# D2522AA register map
Vendor: Dialog; Series: D2522AA; File version: 1.2
CPU: CM0 r1p0, little endian, MPU, FPU, 3 interrupt priority bits
Registers are 32-bit, read-write, reset 0x0 unless marked. A register's access mark holds for its fields unless they carry their own. Offsets are from the block's base; [hi:lo] are bit positions; {n}, {i} and the like mark numbered series; <NAME> marks a mode.

## ADPLL — ADPLL registers
Base 0x40022000
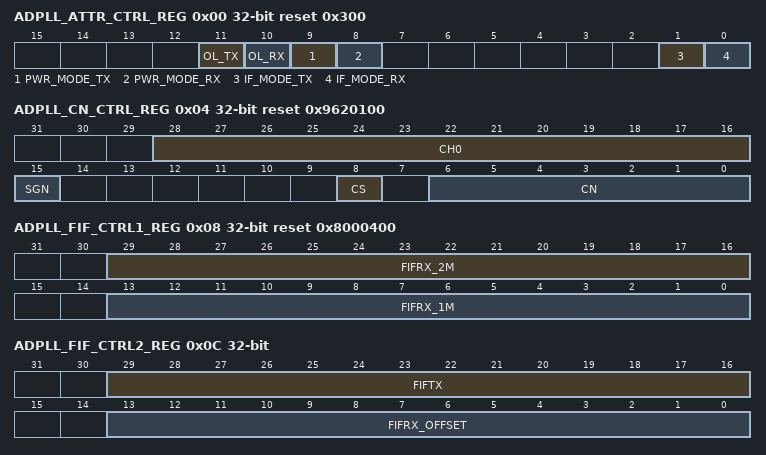
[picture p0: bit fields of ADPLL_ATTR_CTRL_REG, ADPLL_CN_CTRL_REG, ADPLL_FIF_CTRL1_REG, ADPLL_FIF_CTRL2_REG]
0x00 ADPLL_ATTR_CTRL_REG reset 0x300
  [11] OL_TX — Enable open-loop mode for TX. 0: Disabled (default) 1: Enabled
  [10] OL_RX — Enable open-loop mode for RX. 0: Disabled (default) 1: Enabled
  [9] PWR_MODE_TX — Power mode option to be used in TX. 0: Low power (default) 1: High performance
  [8] PWR_MODE_RX — Power mode option to be used in RX. 0: Low power (default) 1: High performance
  [1] IF_MODE_TX — IF mode option to be used in TX. 0: 1 Mbps (default) 1: 2 Mbps
  [0] IF_MODE_RX — IF mode option to be used in RX. 0: 1 Mbps (default) 1: 2 Mbps
0x04 ADPLL_CN_CTRL_REG reset 0x9620100
  [28:16] CH0 — Channel 0 frequency in MHz (CH0) (ufix13) default: 2402
  [15] SGN — Sign bit for the channel step 0: positive (default) 1: negative
  [8] CS — Channel spacing. 0: 1 MHz spacing 1: 2 MHz spacing (default)
  [6:0] CN — Channel number. Default: 0
0x08 ADPLL_FIF_CTRL1_REG reset 0x8000400
  [29:16] FIFRX_2M — IF frequency (in MHz) used in 2 Mbps RX mode sfix(14,10) - 1 bit sign, 3 bits integer, 10 bits fractional for MHz unit.
  [13:0] FIFRX_1M — IF frequency (in MHz) used in 1 Mbps RX mode sfix(14,10) - 1 bit sign, 3 bits integer, 10 bits fractional for MHz unit.
0x0C ADPLL_FIF_CTRL2_REG
  [29:16] FIFTX — IF frequency (in MHz) used in TX mode sfix(14,10) - 1 bit sign, 3 bits integer, 10 bits fractional for MHz unit.
  [13:0] FIFRX_OFFSET — Offset for the IF frequency (in MHz) in RX mode. sfix(14,10) - 1 bit sign, 3 bits integer, 10 bits fractional for MHz unit.
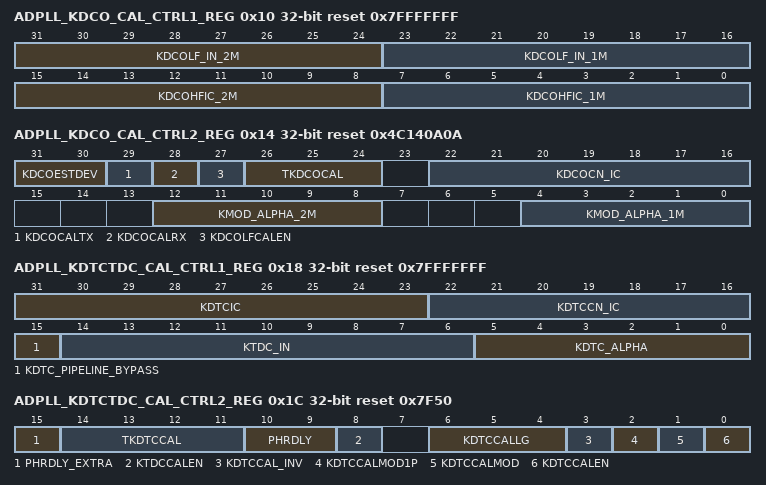
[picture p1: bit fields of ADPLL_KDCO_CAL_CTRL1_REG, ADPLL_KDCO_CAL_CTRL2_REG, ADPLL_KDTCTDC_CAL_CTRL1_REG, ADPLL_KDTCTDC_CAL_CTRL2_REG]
0x10 ADPLL_KDCO_CAL_CTRL1_REG reset 0x7FFFFFFF (reset mask 0x7FFFFFFF)
  [31:24] KDCOLF_IN_2M — Gain setting for the low frequency path in case of not using the calibrated KDCOHF for 2M mode (uint8).
  [23:16] KDCOLF_IN_1M — Gain setting for the low frequency path in case of not using the calibrated KDCOHF for 1M mode (uint8).
  [15:8] KDCOHFIC_2M — Initial gain setting for the high frequency path for 2M mode (uint8).
  [7:0] KDCOHFIC_1M — Initial gain setting for the high frequency path for 1M mode (uint8).
0x14 ADPLL_KDCO_CAL_CTRL2_REG reset 0x4C140A0A (reset mask 0x7FFFFFFF)
  [31:30] KDCOESTDEV — Frequency deviation used for KDCO estimation: 0: 500 kHz 1: 250 kHz (default) 2: 125 kHz 3: 62.5 kHz
  [29] KDCOCALTX — Enable for KDCO calibration in transmit mode.
  [28] KDCOCALRX — Enable for KDCO calibration in receive mode.
  [27] KDCOLFCALEN — Enable the use of the (calibrated) value for KDCOHF for the low frequency path.
  [26:24] TKDCOCAL — Time spend for KDCO calibration settling: 0: 0.5 us 16 1: 1 us 32 2: 2 us 64 3: 4 us 128 4: 8 us
  [22:16] KDCOCN_IC — Initial condition for channel number related to calibration result.
  [12:8] KMOD_ALPHA_2M — KDCOHF channel dependent trimming constant for 2M mode. 0: No trimming. >0: KDCOHF is modified with a factor: 1-SGNx(KMOD_ALPHA_2M)x(CN-CN_CAL_RD)/4096
  [4:0] KMOD_ALPHA_1M — KDCOHF channel dependent trimming constant for 1M mode. 0: No trimming. >0: KDCOHF is modified with a factor: 1-SGNx(KMOD_ALPHA_1M)x(CN-CN_CAL_RD)/4096
0x18 ADPLL_KDTCTDC_CAL_CTRL1_REG reset 0x7FFFFFFF (reset mask 0x7FFFFFFF)
  [31:23] KDTCIC — Initial condition for the DTC gain correction.
  [22:16] KDTCCN_IC — Initial condition for channel number related to calibration result.
  [15] KDTC_PIPELINE_BYPASS — Bypass the extra register on prv_phr.
  [14:6] KTDC_IN — TDC gain setting in case of not using the calibrated gain setting.
  [5:0] KDTC_ALPHA — KDTC channel dependent trimming constant. 0: No trimming. >0: KDTC is modified with a factor: 1-SGNx(KDTC_ALPHA)x(CN-CN_CAL_RD)/16384
0x1C ADPLL_KDTCTDC_CAL_CTRL2_REG reset 0x7F50
  [15] PHRDLY_EXTRA
  [14:11] TKDTCCAL — Time spend waiting for DTC calibration (0-15) 0 - 15 us t = tkdtccal/2.
  [10:9] PHRDLY — Delay phr used for kdtc calibration by 1-4 samples, default: 3 samples (2).
  [8] KTDCCALEN — Enable calibration of TDC via DTC calibration.
  [6:4] KDTCCALLG — Loopgain setting used for DTC calibration.
  [3] KDTCCAL_INV — Invert sign of kdtc calibration loop (default: 0).
  [2] KDTCCALMOD1P — Chicken bit to change phase of KDTC cal mode 1 phase.
  [1] KDTCCALMOD — Mode select for KDTC alogrithm: 0: Just-in-time algorithm (least intrusive) 1: Interger lock to Fref/2 and use second clock phase for calibration (no issue with local optimum)
  [0] KDTCCALEN — Enable DTC calibration.
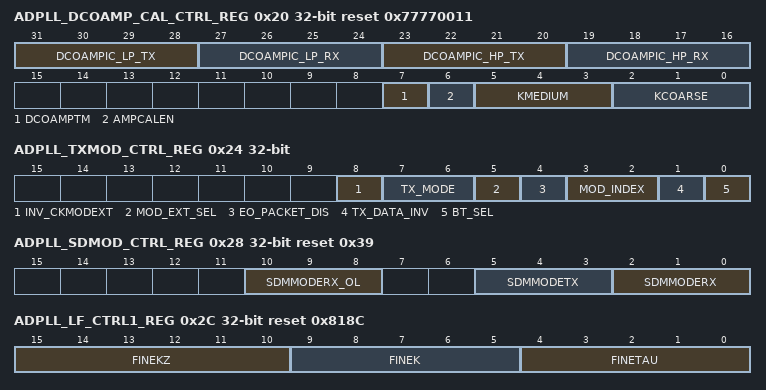
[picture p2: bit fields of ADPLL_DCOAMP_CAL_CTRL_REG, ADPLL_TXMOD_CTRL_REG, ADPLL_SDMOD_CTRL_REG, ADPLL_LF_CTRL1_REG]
0x20 ADPLL_DCOAMP_CAL_CTRL_REG reset 0x77770011 (reset mask 0x7FFFFFFF)
  [31:28] DCOAMPIC_LP_TX — Initial condition for the DCO amplitude setting, for Low Power TX mode..
  [27:24] DCOAMPIC_LP_RX — Initial condition for the DCO amplitude setting, for Low Power RX mode..
  [23:20] DCOAMPIC_HP_TX — Initial condition for the DCO amplitude setting, for High Performance TX mode..
  [19:16] DCOAMPIC_HP_RX — Initial condition for the DCO amplitude setting, for High Performance RX mode..
  [7] DCOAMPTM — Time spend to perform DCO amplitude calibration 0: 1 us 1: 2 us
  [6] AMPCALEN — Enable DCO amplitude calibration.
  [5:3] KMEDIUM — Proportional gain setting for medium tuning.
  [2:0] KCOARSE — Proportional gain setting for coarse tuning.
0x24 ADPLL_TXMOD_CTRL_REG
  [8] INV_CKMODEXT — Invert the clock, which captures the external modulated data.
  [7:6] TX_MODE — Two-point modulation MUX: 0,3: mod_hf = mod_in mod_lf = mod_in 1: mod_hf = 0 mod_lf = mod_in 2: mod_hf = mod_in mod_lf = 0
  [5] MOD_EXT_SEL — 0: Normal operation 1: User externally provided value for the modulation
  [4] EO_PACKET_DIS — The block will normally detect the end of a data packet by the missing tx_data_en pulses. The outputs will be smoothly return to zero when an end of a data packet has been deteted. The end of a data packet detected can be disabled by setting eo_packet_dis = 1. This is normally/never used and eo_packet_dis should always be set to zero.
  [3:2] MOD_INDEX — Modulation index selection: 0: h = 1/2 (dF = 250 kHz) 1 h = 1/4 (dF = 125 kHz): 2: h = 17/32 (dF = 266 kHz) 3: h = 35/64 (dF = 273 kHz)
  [1] TX_DATA_INV — Select polarity of the modulation prior to pulse shaping 0: Normal operation 1: Invert modulation signal
  [0] BT_SEL — The BT product for the Gaussian pulse can take the values 0.5 or 0.6. 0: BT = 0.5 1: BT = 0.6
0x28 ADPLL_SDMOD_CTRL_REG reset 0x39
  [10:8] SDMMODERX_OL — Open Loop Sigma delta modulator mode : 0: Disabled 1: MASH I 3: MASH II 5: MASH I + with dithering 7: MASH II + with dithering
  [5:3] SDMMODETX — Sigma delta modulator mode : 0: Disabled 1: MASH I 3: MASH II 5: MASH I + with dithering 7: MASH II + with dithering
  [2:0] SDMMODERX — Sigma delta modulator mode : 0: Disabled 1: MASH I 3: MASH II 5: MASH I + with dithering 7: MASH II + with dithering
0x2C ADPLL_LF_CTRL1_REG reset 0x818C
  [15:10] FINEKZ — Corner frequency setting of the first order low-pass filter that is used for tuning the fine bank.
  [9:5] FINEK — Loopfilter loopgain frequency during fine tuning.
  [4:0] FINETAU — First order low-pass filter c.rst_ner frequency during fine tuning.
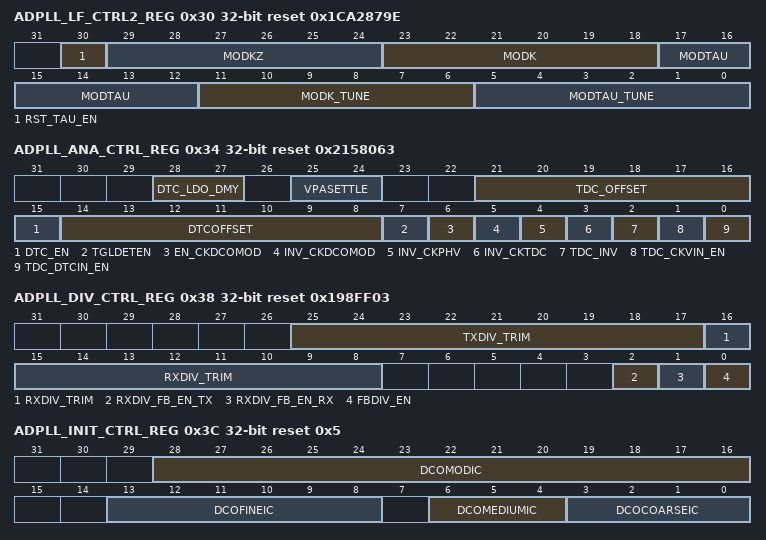
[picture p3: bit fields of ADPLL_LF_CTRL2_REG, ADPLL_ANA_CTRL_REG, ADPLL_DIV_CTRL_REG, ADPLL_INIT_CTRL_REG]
0x30 ADPLL_LF_CTRL2_REG reset 0x1CA2879E
  [30] RST_TAU_EN — Enable state machine to control reset of tau filter.
  [29:24] MODKZ — Loopgain setting of the loop-filter that is used for tuning the MOD bank.
  [23:18] MODK — Corner frequency setting of the zero filter that is used for tuning the MOD bank.
  [17:12] MODTAU — Corner frequency setting of the first order low-pass filter that is used for tuning the MOD bank.
  [11:6] MODK_TUNE — Loopfilter loopgain frequency during mod tuning.
  [5:0] MODTAU_TUNE — First order low-pass filter c.rst_ner frequency during mod tuning.
0x34 ADPLL_ANA_CTRL_REG reset 0x2158063
  [28:27] DTC_LDO_DMY — Control signal for TDC/DTC/VPA LDO dummy loads.
  [25:24] VPASETTLE — Allow TDC after an edge on VPA en 00: No 01: Rising 10: Falling 11: Both edges
  [21:16] TDC_OFFSET — TDC offset that is to be subtracted from the binary input to obtain the signed value (default 10.5).
  [15] DTC_EN — Enable DTC
  [14:8] DTCOFFSET — Offset Added to DTC output Only used for test purpose default = 0
  [7] TGLDETEN — Enable PHV toggle and TDC Bubble detection.
  [6] EN_CKDCOMOD — Enable clock registering the dcomod (default = 1).
  [5] INV_CKDCOMOD — Invert clock polarity of the clock registering the dcomod.
  [4] INV_CKPHV — Invert clock polarity of the clock registering the variable phase accumulator.
  [3] INV_CKTDC — Invert clock polarity of the clock registering the time to digital converter.
  [2] TDC_INV — Invert sign of the time to digital converter output.
  [1] TDC_CKVIN_EN — Enable ckv input of the TDC.
  [0] TDC_DTCIN_EN
0x38 ADPLL_DIV_CTRL_REG reset 0x198FF03
  [25:17] TXDIV_TRIM — Tx divider trim value.
  [16:8] RXDIV_TRIM — Rx divider trim value.
  [2] RXDIV_FB_EN_TX — Enable rxdiv for FB in TX mode. 0: Disable (default) 1: Enable
  [1] RXDIV_FB_EN_RX — Enable rxdiv for FB in RX mode. 0: Disable (default) 1: Enable
  [0] FBDIV_EN — Feedback divider enable 1: Enabled 0: Disabled. If diabled both feedback and RF output clock will be disabled. This bit is intended for test purposes (not for normal usage).
0x3C ADPLL_INIT_CTRL_REG reset 0x5
  [28:16] DCOMODIC — Initial condition for fine cap bank. (signed)
  [13:8] DCOFINEIC — Initial condition for fine cap bank. (signed)
  [6:4] DCOMEDIUMIC — Initial condition for medium cap bank. (signed)
  [3:0] DCOCOARSEIC — Initial condition for coarse cap bank. (signed)
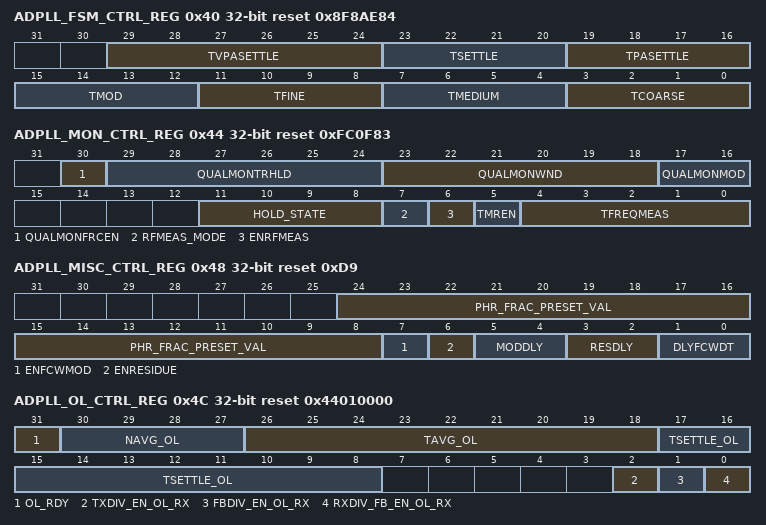
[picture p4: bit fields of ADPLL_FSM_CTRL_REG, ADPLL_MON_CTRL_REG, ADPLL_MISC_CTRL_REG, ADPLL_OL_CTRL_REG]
0x40 ADPLL_FSM_CTRL_REG reset 0x8F8AE84
  [29:24] TVPASETTLE — Settling time required after vpa disable.
  [23:20] TSETTLE — Time spend waiting for settling 0 - 15: 0 - 7.5 us (t = TSETTLE/2)
  [19:16] TPASETTLE — Time spend waiting for PA to settle 0 - 15: 0 - 7.5 us (t = TPASETTLE/2)
  [15:12] TMOD — Time spend for fine tuning 0 - 15: 0 - 15 us (t = TMOD)
  [11:8] TFINE — Time spend for fine tuning 0 - 15: 0 - 15 us (t = TFINE)
  [7:4] TMEDIUM — Time spend for medium tuning 0 - 15: 0 - 7.5 us (t = TMEDIUM/2) If < 1 us and amplitude calibration is enabled TMEDIUM = 1 us.
  [3:0] TCOARSE — Time spend for coarse tuning 0 - 15: 0 - 7.5 us (t = TCOARSE/2)
0x44 ADPLL_MON_CTRL_REG reset 0xFC0F83
  [30] QUALMONFRCEN — Force enable of the clock quality monitor.
  [29:24] QUALMONTRHLD — Clock quality monitoring threshold.
  [23:18] QUALMONWND — Clock quality monitoring window length.
  [17:16] QUALMONMOD — Clock quality monitoring mode: 0: Highpass output 1: TDC 2: Lowpass output 3: Loop filter output
  [11:8] HOLD_STATE — Set a break point at which the tuning state machine will hold it's state.
  [7] RFMEAS_MODE — RF measurement mode for the Divider calibrations. 0 : Jerzy RF measurement. 1 (default): RF measurement for divider calibration.
  [6] ENRFMEAS — Enable open loop frequency measurement.
  [5] TMREN — Enable timer for measuring PLL settling time.
  [4:0] TFREQMEAS — Frequency measurement time Two lsb's form the linear part, the three MSB's are the exponent Time [us] = 0.5+((4+lin)*(2^(exp-1))) tfreqmeas Time [us] 0: 2.5 1: 3 2: 3.5 3: 4 4: 4.5 5: 5.5 6: 6.5 7: 7.5 8: 8.5 9: 10.5 10: 12.5 11: 14.5 12: 16.5 13: 20.5 14: 24.5 15: 28.5 16: 32.5 17: 40.5 18: 48.5 19: 56.5 20: 64.5 21: 80.5 22: 96.5 23: 112.5 24: 128.5 25: 160.5 26: 192.5 27: 224.5 28: 256.5 29: 320.5 30: 384.5 31: 448.5
0x48 ADPLL_MISC_CTRL_REG reset 0xD9
  [24:8] PHR_FRAC_PRESET_VAL — Controls the set level of the DCO amplitude detector.
  [7] ENFCWMOD — Enable two point modulation.
  [6] ENRESIDUE — Enable residue correction .
  [5:4] MODDLY — Delay modulation (injected at the capcitor bank) by 0-3 samples.
  [3:2] RESDLY — Delay residue by 0-3 samples.
  [1:0] DLYFCWDT — Delay reference path of the two point modulation.
0x4C ADPLL_OL_CTRL_REG reset 0x44010000 (reset mask 0x7FFFFFFF)
  [31] OL_RDY ro — Read out openloop_rdy output before gating with rxbit status.
  [30:27] NAVG_OL — Averaging ratio. Division for averaging: 2NAVG_OL.
  [26:18] TAVG_OL — Number of dcomod samples to be averaged. TAVG_OL = 2NAVG_OL)
  [17:8] TSETTLE_OL — Number of clocks cycles to wait for dcomod to settle, before starting averaging for open loop mode.
  [2] TXDIV_EN_OL_RX — txdiv_en value to be used in open loop mode when in RX.
  [1] FBDIV_EN_OL_RX — fbdiv_en value to be used in open loop mode when in RX.
  [0] RXDIV_FB_EN_OL_RX — rxdiv_fb_en value to be used in open loop mode when in RX.
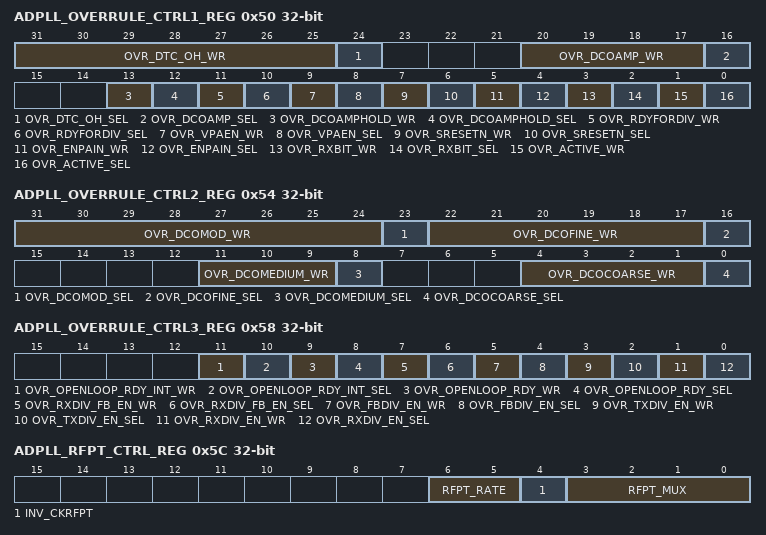
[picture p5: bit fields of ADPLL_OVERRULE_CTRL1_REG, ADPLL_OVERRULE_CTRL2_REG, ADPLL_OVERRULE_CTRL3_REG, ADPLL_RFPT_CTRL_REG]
0x50 ADPLL_OVERRULE_CTRL1_REG (reset mask 0x7FFFFFFF)
  [31:25] OVR_DTC_OH_WR — Overrule value (binary) for the dtc_oh.
  [24] OVR_DTC_OH_SEL — Overrule dtc_oh output. 0: Normal function (default) 1: Overrule dtc_oh output by OVR_DTC_OH_WR
  [20:17] OVR_DCOAMP_WR — Overrule value for the dcoamp.
  [16] OVR_DCOAMP_SEL — Overrule dcoamp output. 0: Normal function (default) 1: Overrule dcoamp output by OVR_DCOAMP_WR
  [13] OVR_DCOAMPHOLD_WR — Overrule value for the dcoamp_hold..
  [12] OVR_DCOAMPHOLD_SEL — Overrule dcoamphold output. 0: Normal function (default) 1: Overrule dcoamphold output by OVR_DCOAMPHOLD_WR
  [11] OVR_RDYFORDIV_WR — Overrule value for the rdy_for_div input.
  [10] OVR_RDYFORDIV_SEL — Overrule rdy_for_div input. 0: Normal function (default) 1: Overrule rdy_for_div input by OVR_RDYFORDIV_WR
  [9] OVR_VPAEN_WR — Overrule value for the vpa_en.
  [8] OVR_VPAEN_SEL — Overrule vpaen. 0: Normal function (default) 1: Overrule vpaen by OVR_VPAEN_WR
  [7] OVR_SRESETN_WR — Overrule value for the sreset_n.
  [6] OVR_SRESETN_SEL — Overrule sreset_n of the modulator. 0: Normal function (default) 1: Overrule sreset_n by OVR_SRESETN_WR
  [5] OVR_ENPAIN_WR — Overrule value for the enpain.
  [4] OVR_ENPAIN_SEL — Overrule enpain input. 0: Normal function (default) 1: Overrule enpain input by OVR_ENPAIN_WR
  [3] OVR_RXBIT_WR — Overrule value for the rxbit.
  [2] OVR_RXBIT_SEL — Overrule rxbit input. 0: Normal function (default) 1: Overrule rxbit input by OVR_RXBIT_WR
  [1] OVR_ACTIVE_WR — Overrule value for the active.
  [0] OVR_ACTIVE_SEL — Overrule active input. 0: Normal function (default) 1: Overrule active input by OVR_ACTIVE_WR
0x54 ADPLL_OVERRULE_CTRL2_REG (reset mask 0x7FFFFFFF)
  [31:24] OVR_DCOMOD_WR — Overrule value (binary) for the internal dcomod.
  [23] OVR_DCOMOD_SEL — Overrule dcomod output. 0: Normal function (default) 1: Overrule dcomod output by OVR_DCOMOD_WR
  [22:17] OVR_DCOFINE_WR — Overrule value (binary) for the internal dcofine.
  [16] OVR_DCOFINE_SEL — Overrule dcomod output. 0: Normal function (default) 1: Overrule dcomod output by OVR_DCOFINE_WR
  [11:9] OVR_DCOMEDIUM_WR — Overrule value (binary) for the internal dcomedium.
  [8] OVR_DCOMEDIUM_SEL — Overrule dcomod output. 0: Normal function (default) 1: Overrule dcomod output by OVR_DCOMEDIUM_WR
  [4:1] OVR_DCOCOARSE_WR — Overrule value (binary) for the internal dcocoarse.
  [0] OVR_DCOCOARSE_SEL — Overrule dcomod output. 0: Normal function (default) 1: Overrule dcomod output by OVR_DCOCOARSE_WR
0x58 ADPLL_OVERRULE_CTRL3_REG
  [11] OVR_OPENLOOP_RDY_INT_WR — Overrule value for the internal openloop_rdy.
  [10] OVR_OPENLOOP_RDY_INT_SEL — Overrule internal openloop_rdy. 0: Normal function (default) 1: Overrule internal openloop_rdy by OVR_OPENLOOP_RDY_INT_WR
  [9] OVR_OPENLOOP_RDY_WR — Overrule value for the openloop_rdy output.
  [8] OVR_OPENLOOP_RDY_SEL — Overrule openloop_rdy output. 0: Normal function (default) 1: Overrule openloop_rdy output by OVR_OPENLOOP_RDY_WR
  [7] OVR_RXDIV_FB_EN_WR — Overrule value for the rxdiv_fb_en output.
  [6] OVR_RXDIV_FB_EN_SEL — Overrule rxdiv_fb_en output. 0: Normal function (default) 1: Overrule rxdiv_fb_en output by OVR_RXDIV_FB_EN_WR
  [5] OVR_FBDIV_EN_WR — Overrule value for the fbdiv_en output.
  [4] OVR_FBDIV_EN_SEL — Overrule fbdiv_en output. 0: Normal function (default) 1: Overrule fbdiv_en output by OVR_FBDIV_EN_WR
  [3] OVR_TXDIV_EN_WR — Overrule value for the txdiv_en output.
  [2] OVR_TXDIV_EN_SEL — Overrule txdiv_en output. 0: Normal function (default) 1: Overrule txdiv_en output by OVR_TXDIV_EN_WR
  [1] OVR_RXDIV_EN_WR — Overrule value for the rxdiv_en output.
  [0] OVR_RXDIV_EN_SEL — Overrule rxdiv_en. 0: Normal function (default) 1: Overrule rxdiv_en output by OVR_RXDIV_EN_WR
0x5C ADPLL_RFPT_CTRL_REG
  [6:5] RFPT_RATE — RFPT rate setting 0: 32MSPS 1: 16 MSPS
  [4] INV_CKRFPT — Invert clock registering output of the RFPT interface.
  [3:0] RFPT_MUX — Multiplexer setting for RFPT interface output. The following data will be provided to the rfpt interface: 0: RFPT disabled (default) 1: {tdc_invert,tdc_b,tdc_t_reg} 2: {8'd0, dcocoarse, 1'd0,dcomedium, 2'd0,dcofine, dcomod_sdm} 3: {2'd0, phe_int, 1'd0,phv_int, 1'd0,phr_int0, phe_int_int} 4: {lfout_int,lfout_frac,int_state,lpout,kdtc_int} 5, ..., 15: Reserved.
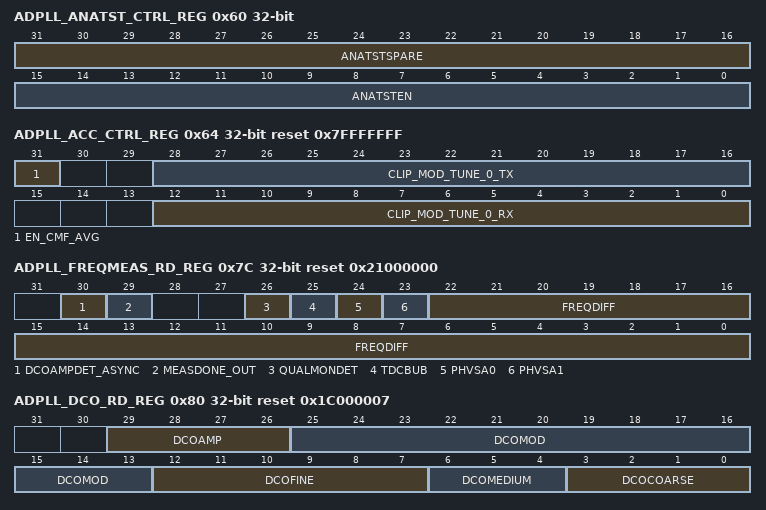
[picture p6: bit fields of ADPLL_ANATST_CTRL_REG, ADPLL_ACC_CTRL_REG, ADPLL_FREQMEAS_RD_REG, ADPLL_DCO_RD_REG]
0x60 ADPLL_ANATST_CTRL_REG (reset mask 0x7FFFFFFF)
  [31:16] ANATSTSPARE — Analog test spare outputs.
  [15:0] ANATSTEN — Analog test enable outputs.
0x64 ADPLL_ACC_CTRL_REG reset 0x7FFFFFFF (reset mask 0x7FFFFFFF)
  [31] EN_CMF_AVG — Enable CMF averaging. 0: Disabled (default) 1: Enabled
  [28:16] CLIP_MOD_TUNE_0_TX — Clipping value for mod_tune 0 in TX mode.
  [12:0] CLIP_MOD_TUNE_0_RX — Clipping value for mod_tune 0 in RX mode.
0x7C ADPLL_FREQMEAS_RD_REG reset 0x21000000
  [30] DCOAMPDET_ASYNC ro — DCO amplitude detector input (Used for amplitude calibration)
  [29] MEASDONE_OUT ro — Signal indicating the state of the frequency counter 0: Measuring frequency 1: Measurement done
  [26] QUALMONDET ro — Clock quality monitoring detector output.
  [25] TDCBUB ro — Detector output indicating a bubble error in the TDC input.
  [24] PHVSA0 ro — Detector output indicating a stuck-at 0 on the variable phase accumulator input .
  [23] PHVSA1 ro — Detector output indicating a stuck-at 1 on the variable phase accumulator input .
  [22:0] FREQDIFF ro — Measurend frequency difference (signed).
0x80 ADPLL_DCO_RD_REG reset 0x1C000007
  [29:26] DCOAMP ro — DCO amplitude setting. The read value is the output of adplldig (towards the analog). So, the read value is even after the overruling.
  [25:13] DCOMOD ro — Current state of the DCO mod capacitor bank (signed) The open-loop output (before the addition of modulated data). So, it is after averaging, before SDM and addition of the modulated data.
  [12:7] DCOFINE ro — Current state of the DCO fine capacitor bank (signed) ACC outputs are read (the averaged values.) For CMF we are reading before bin2thm conversion
  [6:4] DCOMEDIUM ro — Current state of the DCO medium capacitor bank (signed) ACC outputs are read (the averaged values.) For CMF we are reading before bin2thm conversion
  [3:0] DCOCOARSE ro — Current state of the DCO coarse capacitor bank (signed) ACC outputs are read (the averaged values.) For CMF we are reading before bin2thm conversion
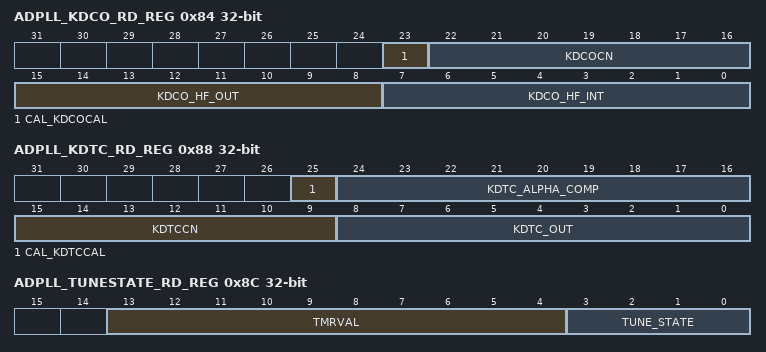
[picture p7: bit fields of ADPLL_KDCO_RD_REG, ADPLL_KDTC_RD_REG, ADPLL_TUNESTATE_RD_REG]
0x84 ADPLL_KDCO_RD_REG
  [23] CAL_KDCOCAL ro — Calibration state of the KDCO calibration.
  [22:16] KDCOCN ro — Channel number related to calibration result.
  [15:8] KDCO_HF_OUT ro — kmod_alpha compensated KDCO gain.
  [7:0] KDCO_HF_INT ro — KDCO gain.
0x88 ADPLL_KDTC_RD_REG
  [25] CAL_KDTCCAL ro — Calibration state of the KDTC calibration.
  [24:16] KDTC_ALPHA_COMP ro — KDTC_ALPHA compensated DTC gain setting. Used as TDC gain setting used to correct loopgain.
  [15:9] KDTCCN ro — Channel number related to calibration result.
  [8:0] KDTC_OUT ro — DTC gain setting updated in tuning state 13. Used for register readback.
0x8C ADPLL_TUNESTATE_RD_REG
  [13:4] TMRVAL ro — Current timer value. Timer can be used to determine PLL settling time and is used for frequency measurement.
  [3:0] TUNE_STATE ro — Binary coded state of the tuning state machine.
0x90 ADPLL_PLLFCWDT_RD_REG reset 0x258800
  [22:0] PLLFCWDT ro
0x94 ADPLL_ANATST_RD_REG
  [15:0] ANATSTSPARE_IN ro — Ana test spare in.
